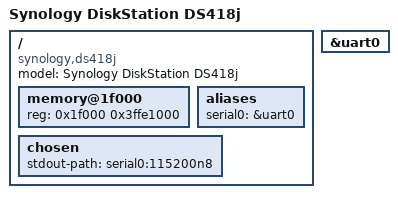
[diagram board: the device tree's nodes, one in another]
/dts-v1/;
#include "rtd1293.dtsi"
/ {
	compatible = "synology,ds418j", "realtek,rtd1293";
	model = "Synology DiskStation DS418j";
	memory@1f000 {
		device_type = "memory";
		reg = <0x1f000 0x3ffe1000>;  
	};
	aliases {
		serial0 = &uart0;
	};
	chosen {
		stdout-path = "serial0:115200n8";
	};
};
&uart0 {
	status = "okay";
};
